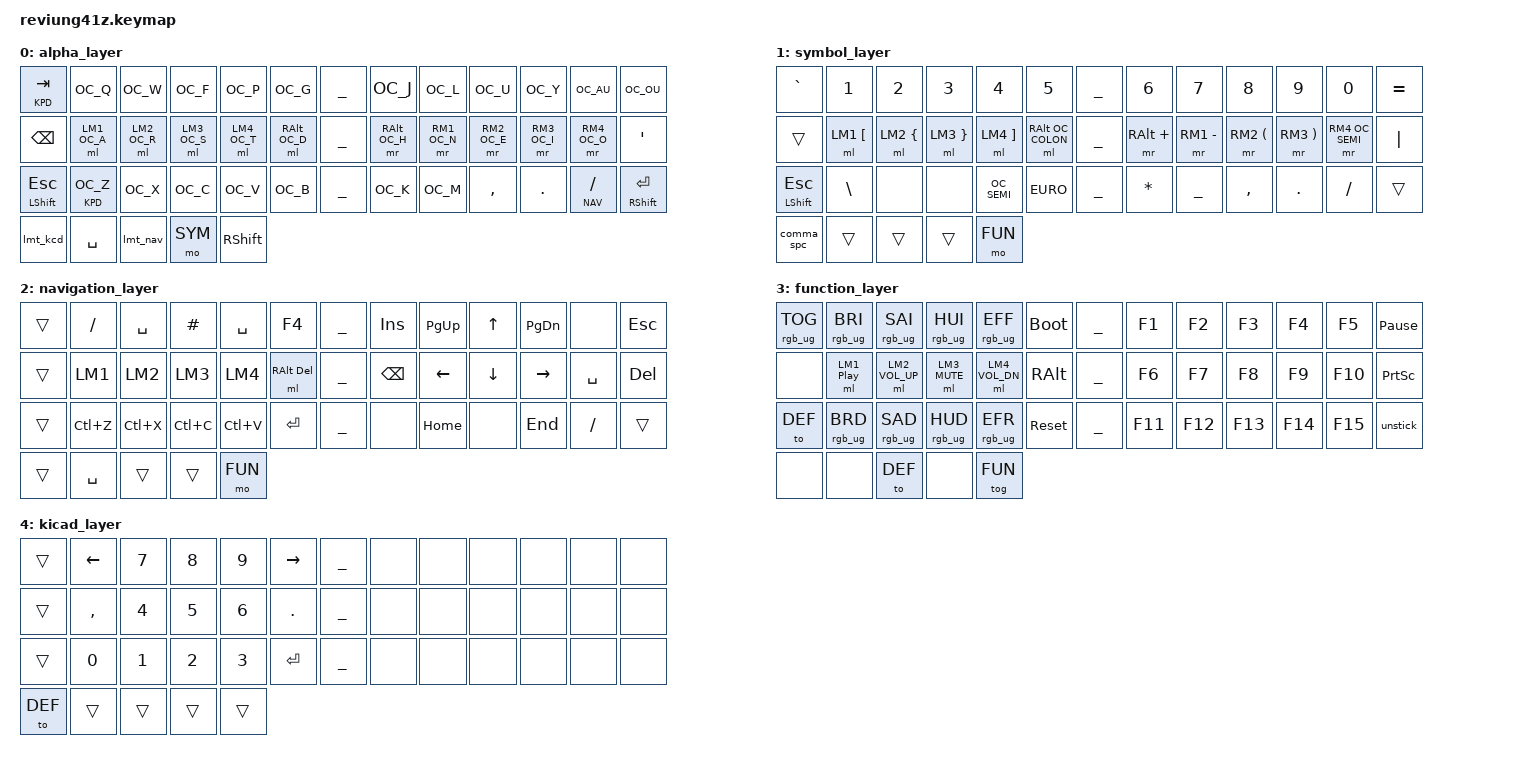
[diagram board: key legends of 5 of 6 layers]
/*
 * Copyright (c) 2020 The ZMK Contributors
 *
 * SPDX-License-Identifier: MIT
 */

#include <behaviors.dtsi>
#include <dt-bindings/zmk/keys.h>
#include <dt-bindings/zmk/bt.h>
#include <dt-bindings/zmk/rgb.h>

#include "lib/base.h"
// https://github.com/joelspadin/zmk-locale-generator
// # include "keys_fi.h"
#include "lib/keys_os_colemak.h"

#define DEF 0
#define SYM 1
#define NAV 2
#define FUN 3
#define KCD 4
#define KPD 5

#define LAYERS_ALL DEF SYM NAV KCD FUN KPD
#define LAYERS_ALPHANUM DEF SYM KPD

#define KEYS_L 0 1 2 3 4 5  12 13 14 15 16 17  24 25 26 27 28 29
#define KEYS_R 6 7 8 9 10 11  18 19 20 21 22 23  30 31 32 33 34 35
#define KEYS_T 36 37 38 39 40

/ {
	behaviors {
		#include "lib/behaviors.dtsi"
	};

	// -----------------------------------------------------------------------------------------
	// | 0   | 1   | 2   | 3   | 4   | 5   |     | 6   | 7   | 8   | 9   | 10  | 11  |
	// | 12  | 13  | 14  | 15  | 16  | 17  |     | 18  | 19  | 20  | 21  | 22  | 23  |
	// | 24  | 25  | 26  | 27  | 28  | 29  |     | 30  | 31  | 32  | 33  | 34  | 35  |
	//                         | 36  | 37  | 38  | 39  | 40  |
	combos {
		compatible = "zmk,combos";

		#include "lib/combos.dtsi"

		//COMBO_S(backspace, &kp BSPC, 13 14, LAYERS_ALPHANUM)

		COMBO_L(lbkt, &kp LBKT, 1 2, LAYERS_ALPHANUM)
		COMBO_L(semi, &kp OC_SEMI, 2 3, LAYERS_ALPHANUM)
		COMBO_S(rbkt, &kp RBKT, 3 4, LAYERS_ALPHANUM)
		COMBO_L(lpar, &kp LPAR, 25 26, LAYERS_ALPHANUM)
		COMBO_S(colon, &kp OC_COLON, 26 27, LAYERS_ALPHANUM)
		COMBO_S(rpar, &kp RPAR, 27 28, LAYERS_ALPHANUM)

		COMBO_S(lbrc, &kp LBRC, 7 8, LAYERS_ALPHANUM)
		COMBO_L(rbrc, &kp RBRC, 9 10, LAYERS_ALPHANUM)
		//COMBO_S(semi, &kp OC_SEMI, 9 10, LAYERS_ALPHANUM)
		COMBO_S(lt, &kp LT, 31 32, LAYERS_ALPHANUM)
		COMBO_L(gt, &kp GT, 33 34, LAYERS_ALPHANUM)
		//COMBO_S(ret, &kp RET, 33 34, LAYERS_ALL)
	};

	macros {
		#include "lib/macros.dtsi"
	};

	// Keymap assumes Colemak on OS side, as I also use regular keyboards
	keymap {
		compatible = "zmk,keymap";

// Colemak on OS side
// |     |  Q  |  W  |  F  |  P  |  G  |   |  J  |  L  |  U  |  Y  |  Ä  |  Ö  |
// |     |  A  |  R  |  S  |  T  |  D  |   |  H  |  N  |  E  |  I  |  O  |  '  |
// |     |  Z  |  X  |  C  |  V  |  B  |   |  K  |  M  |  ,  |  .  |  /  |     |
		alpha_layer {
			bindings = <
&lt KPD TAB    &kp OC_Q     &kp OC_W     &kp OC_F     &kp OC_P     &kp OC_G      ___  &kp OC_J      &kp OC_L     &kp OC_U     &kp OC_Y     &kp OC_AU    &kp OC_OU
&kp BSPC       &ml LM1 OC_A &ml LM2 OC_R &ml LM3 OC_S &ml LM4 OC_T &ml RALT OC_D ___  &mr RALT OC_H &mr RM1 OC_N &mr RM2 OC_E &mr RM3 OC_I &mr RM4 OC_O &kp SQT
&mt LSHFT ESC  &lt KPD OC_Z &kp OC_X     &kp OC_C     &kp OC_V     &kp OC_B      ___  &kp OC_K      &kp OC_M     &kp COMMA    &kp DOT      &lt NAV FSLH &mt RSHFT RET
&lmt_kcd       &kp SPACE    &lmt_nav     &mo SYM      &kp RSHFT
			>;
		};

//   ~     !     @     #     $     %         ^     &     *     (     )     +
// | `   | 1   | 2   | 3   | 4   | 5   |   | 6   | 7   | 8   | 9   | 0   | =   |
// |     | [   | {   | }   | ]   | :   |   | +   | -   | (   | )   | ;   | |   |
// |     | \   |     |     | ;   | €   |   | *   | _   | ,   | .   | /   |     |
		symbol_layer {
			bindings = <
&kp GRAVE     &kp N1       &kp N2       &kp N3       &kp N4       &kp N5            ___  &kp N6        &kp N7        &kp N8       &kp N9       &kp N0          &kp EQUAL
&trans        &ml LM1 LBKT &ml LM2 LBRC &ml LM3 RBRC &ml LM4 RBKT &ml RALT OC_COLON ___  &mr RALT PLUS &mr RM1 MINUS &mr RM2 LPAR &mr RM3 RPAR &mr RM4 OC_SEMI &kp PIPE
&mt LSHFT ESC &kp BSLH     &none        &none        &kp OC_SEMI  &kp EURO          ___  &kp STAR      &kp UNDER     &kp COMMA    &kp DOT      &kp FSLH        &trans
&comma_spc    &trans       &trans       &trans       &mo FUN
			>;
		};

		navigation_layer {
			bindings = <
&trans  &kp FSLH   &kp SPACE  &kp HASH   &kp SPACE  &kp F4        ___  &kp INS    &kp PG_UP  &kp UP     &kp PG_DN  &none      &kp ESC
&trans  &kp LM1    &kp LM2    &kp LM3    &kp LM4    &ml RALT DEL  ___  &kp BSPC   &kp LEFT   &kp DOWN   &kp RIGHT  &kp SPACE  &kp DEL
&trans  &kp LC(Z)  &kp LC(X)  &kp LC(C)  &kp LC(V)  &kp RET       ___  &none      &kp HOME   &none      &kp END    &kp FSLH   &trans
&trans  &kp SPACE  &trans     &trans     &mo FUN
			>;
		};

		function_layer {
			bindings = <
&rgb_ug RGB_TOG &rgb_ug RGB_BRI      &rgb_ug RGB_SAI  &rgb_ug RGB_HUI &rgb_ug RGB_EFF  &bootloader ___  &kp F1  &kp F2  &kp F3  &kp F4  &kp F5  &kp PAUSE_BREAK
&none           &ml LM1 C_PLAY_PAUSE &ml LM2 C_VOL_UP &ml LM3 C_MUTE  &ml LM4 C_VOL_DN &kp RALT    ___  &kp F6  &kp F7  &kp F8  &kp F9  &kp F10 &kp PRINTSCREEN
&to DEF         &rgb_ug RGB_BRD      &rgb_ug RGB_SAD  &rgb_ug RGB_HUD &rgb_ug RGB_EFR  &sys_reset  ___  &kp F11 &kp F12 &kp F13 &kp F14 &kp F15 &unstick
&none           &none                &to DEF          &none           &tog FUN
			>;
		};

		kicad_layer {
			bindings = <
&trans   &kp LEFT   &kp N7  &kp N8  &kp N9  &kp RIGHT  ___ &none  &none  &none  &none  &none  &none
&trans   &kp COMMA  &kp N4  &kp N5  &kp N6  &kp DOT    ___ &none  &none  &none  &none  &none  &none
&trans   &kp N0     &kp N1  &kp N2  &kp N3  &kp RET    ___ &none  &none  &none  &none  &none  &none
&to DEF  &trans     &trans  &trans  &trans
			>;
		};

		keypad_layer {
			bindings = <
&trans    &kp LALT   &kp PG_UP  &kp UP    &kp PG_DN  &none    ___  &kp KP_NLCK &kp KP_N7  &kp KP_N8  &kp KP_N9  &kp KP_MINUS &kp KP_DIV
&trans    &kp LCTRL  &kp LEFT   &kp DOWN  &kp RIGHT  &kp DEL  ___  &kp KP_DOT  &kp KP_N4  &kp KP_N5  &kp KP_N6  &kp KP_PLUS  &kp KP_MUL
&trans    &kp LGUI   &kp COMMA  &kp SPACE &kp DOT    &kp RET  ___  &kp KP_N0   &kp KP_N1  &kp KP_N2  &kp KP_N3  &kp KP_ENTER &trans
&to DEF   &trans     &trans                                   ___  &kp KP_N0   &kp KP_DOT
			>;
		};
	};
};
